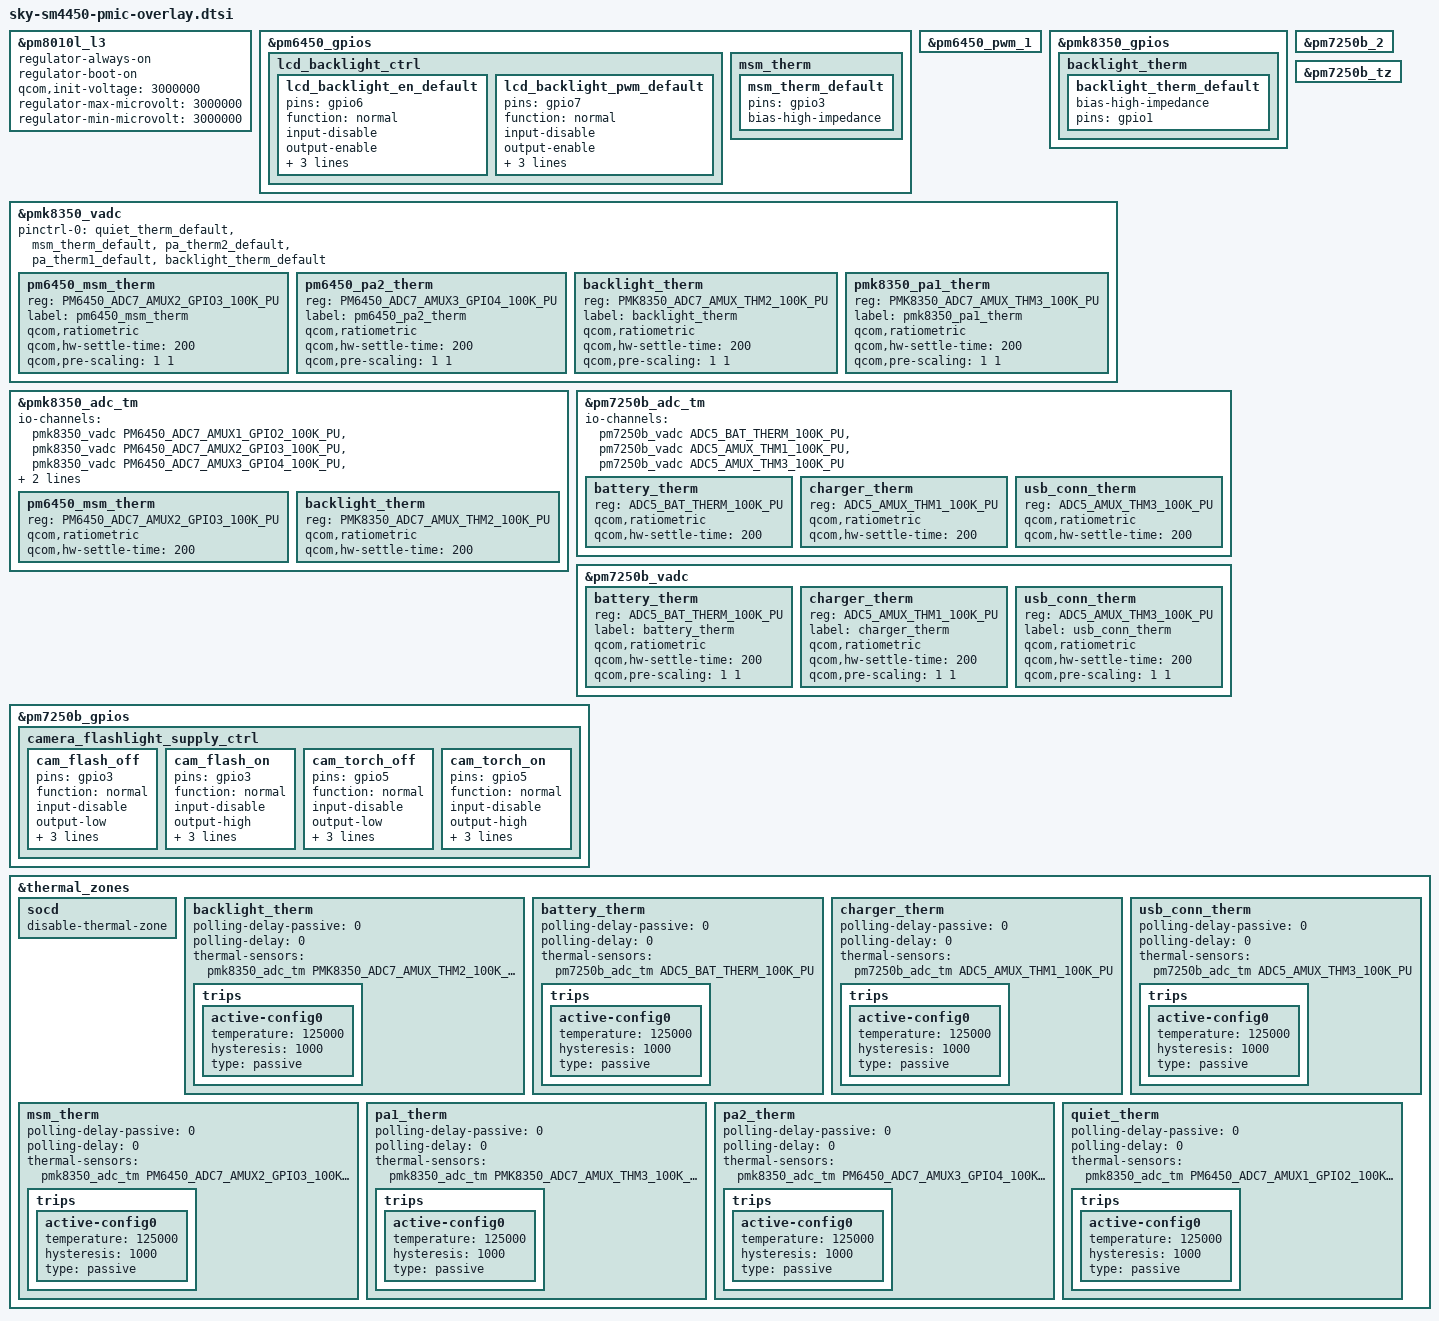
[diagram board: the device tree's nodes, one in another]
/*
 * Copyright (c) 2023 Atom-X-Devs.
 * Divyanshu-Modi <divyan.m05@gmail.com>
 *
 * Xiaomi SM4450 based SKY platform specific
 */

#include "ravelin-pmic-overlay.dtsi"
#include "ravelin-pm7250b.dtsi"

/*
 * PM8010 device specific diff for Xiaomi Sky platform
 */
&pm8010l_l3 {
	regulator-always-on;
	regulator-boot-on;
	qcom,init-voltage = <3000000>;
	regulator-max-microvolt = <3000000>;
	regulator-min-microvolt = <3000000>;
};

/*
 * PM6450 device specific diff for Xiaomi Sky platform
 */
&pm6450_gpios {
	/delete-node/ rear_cam_flash_therm;

	lcd_backlight_ctrl {
		lcd_backlight_en_default: lcd_backlight_en_default {
			pins = "gpio6";
			function = "normal";
			input-disable; /* No PULL */
			output-enable;
			bias-disable;
			power-source = <0>;
			drive-strength = <2>;
		};

		lcd_backlight_pwm_default: lcd_backlight_pwm_default {
			pins = "gpio7";
			function = "normal";
			input-disable; /* No PULL */
			output-enable;
			bias-disable;
			power-source = <1>;
			drive-strength = <2>;
		};
	};

	msm_therm {
		msm_therm_default: msm_therm_default {
			pins = "gpio3";
			bias-high-impedance;
		};
	};
};

&pm6450_pwm_1 {
	status = "ok";
};

/*
 * PMK8350 device specific diff for Xiaomi Sky platform
 */
&pmk8350_gpios {
	/delete-node/ wide_rfc_therm;

	backlight_therm {
		backlight_therm_default: backlight_therm_default {
			bias-high-impedance;
			pins = "gpio1";
		};
	};
};

&pmk8350_vadc {
	pinctrl-names = "default";
	pinctrl-0 = <&quiet_therm_default &msm_therm_default
			&pa_therm2_default &pa_therm1_default &backlight_therm_default>;

	/delete-node/ pmk8350_wide_rfc_therm;
	/delete-node/ pm6450_rear_cam_flash_therm;
	/delete-node/ pm6450_pa_therm2;
	/delete-node/ pmk8350_pa_therm1;

	pm6450_msm_therm {
		reg = <PM6450_ADC7_AMUX2_GPIO3_100K_PU>;
		label = "pm6450_msm_therm";
		qcom,ratiometric;
		qcom,hw-settle-time = <200>;
		qcom,pre-scaling = <1 1>;
	};

	pm6450_pa2_therm {
		reg = <PM6450_ADC7_AMUX3_GPIO4_100K_PU>;
		label = "pm6450_pa2_therm";
		qcom,ratiometric;
		qcom,hw-settle-time = <200>;
		qcom,pre-scaling = <1 1>;
	};

	backlight_therm {
		reg = <PMK8350_ADC7_AMUX_THM2_100K_PU>;
		label = "backlight_therm";
		qcom,ratiometric;
		qcom,hw-settle-time = <200>;
		qcom,pre-scaling = <1 1>;
	};

	pmk8350_pa1_therm {
		reg = <PMK8350_ADC7_AMUX_THM3_100K_PU>;
		label = "pmk8350_pa1_therm";
		qcom,ratiometric;
		qcom,hw-settle-time = <200>;
		qcom,pre-scaling = <1 1>;
	};
};

&pmk8350_adc_tm {
	/delete-node/ pmk8350_xo_therm;
	/delete-node/ pmk8350_wide_rfc_therm;
	/delete-node/ pm6450_rear_cam_flash_therm;

	io-channels = <&pmk8350_vadc PM6450_ADC7_AMUX1_GPIO2_100K_PU>,
			<&pmk8350_vadc PM6450_ADC7_AMUX2_GPIO3_100K_PU>,
			<&pmk8350_vadc PM6450_ADC7_AMUX3_GPIO4_100K_PU>,
			<&pmk8350_vadc PMK8350_ADC7_AMUX_THM2_100K_PU>,
			<&pmk8350_vadc PMK8350_ADC7_AMUX_THM3_100K_PU>;

	pm6450_msm_therm {
		reg = <PM6450_ADC7_AMUX2_GPIO3_100K_PU>;
		qcom,ratiometric;
		qcom,hw-settle-time = <200>;
	};

	backlight_therm {
		reg = <PMK8350_ADC7_AMUX_THM2_100K_PU>;
		qcom,ratiometric;
		qcom,hw-settle-time = <200>;
	};
};

/*
 * PMK7250B device specific diff for Xiaomi Sky platform
 */
&pm7250b_2 {
	/delete-node/ qcom,power-on@800;
};

&pm7250b_tz {
	/delete-property/ interrupts;
};

&pm7250b_adc_tm {
	/delete-node/ pm7250b_usb_conn_therm;
	/delete-node/ pm7250b_charger_skin_therm;

	io-channels = <&pm7250b_vadc ADC5_BAT_THERM_100K_PU>,
			<&pm7250b_vadc ADC5_AMUX_THM1_100K_PU>,
			<&pm7250b_vadc ADC5_AMUX_THM3_100K_PU>;

	battery_therm {
		reg = <ADC5_BAT_THERM_100K_PU>;
		qcom,ratiometric;
		qcom,hw-settle-time = <200>;
	};

	charger_therm {
		reg = <ADC5_AMUX_THM1_100K_PU>;
		qcom,ratiometric;
		qcom,hw-settle-time = <200>;
	};

	usb_conn_therm {
		reg = <ADC5_AMUX_THM3_100K_PU>;
		qcom,ratiometric;
		qcom,hw-settle-time = <200>;
	};
};

&pm7250b_vadc {
	/delete-node/ pm7250b_usb_conn_therm;
	/delete-node/ pm7250b_charger_skin_therm;

	battery_therm {
		reg = <ADC5_BAT_THERM_100K_PU>;
		label = "battery_therm";
		qcom,ratiometric;
		qcom,hw-settle-time = <200>;
		qcom,pre-scaling = <1 1>;
	};

	charger_therm {
		reg = <ADC5_AMUX_THM1_100K_PU>;
		label = "charger_therm";
		qcom,ratiometric;
		qcom,hw-settle-time = <200>;
		qcom,pre-scaling = <1 1>;
	};

	usb_conn_therm {
		reg = <ADC5_AMUX_THM3_100K_PU>;
		label = "usb_conn_therm";
		qcom,ratiometric;
		qcom,hw-settle-time = <200>;
		qcom,pre-scaling = <1 1>;
	};
};

&pm7250b_gpios {
	camera_flashlight_supply_ctrl {
		cam_flash_off: cam_flash_off {
			pins = "gpio3";
			function = "normal";
			input-disable; /* No PULL */
			output-low;
			bias-disable;
			power-source = <0>;
			drive-strength = <2>;
		};

		cam_flash_on: cam_flash_on {
			pins = "gpio3";
			function = "normal";
			input-disable; /* No PULL */
			output-high;
			bias-disable;
			power-source = <0>;
			drive-strength = <2>;
		};

		cam_torch_off: cam_torch_off {
			pins = "gpio5";
			function = "normal";
			input-disable; /* No PULL */
			output-low;
			bias-disable;
			power-source = <0>;
			drive-strength = <2>;
		};

		cam_torch_on: cam_torch_on {
			pins = "gpio5";
			function = "normal";
			input-disable; /* No PULL */
			output-high;
			bias-disable;
			power-source = <0>;
			drive-strength = <2>;
		};
	};
};

&thermal_zones {
	socd {
		disable-thermal-zone;
	};

	backlight_therm {
		polling-delay-passive = <0>;
		polling-delay = <0>;
		thermal-sensors = <&pmk8350_adc_tm PMK8350_ADC7_AMUX_THM2_100K_PU>;
		trips {
			active-config0 {
				temperature = <125000>;
				hysteresis = <1000>;
				type = "passive";
			};
		};
	};

	battery_therm {
		polling-delay-passive = <0>;
		polling-delay = <0>;
		thermal-sensors =  <&pm7250b_adc_tm ADC5_BAT_THERM_100K_PU>;
		trips {
			active-config0 {
				temperature = <125000>;
				hysteresis = <1000>;
				type = "passive";
			};
		};
	};

	charger_therm {
		polling-delay-passive = <0>;
		polling-delay = <0>;
		thermal-sensors =  <&pm7250b_adc_tm ADC5_AMUX_THM1_100K_PU>;
		trips {
			active-config0 {
				temperature = <125000>;
				hysteresis = <1000>;
				type = "passive";
			};
		};
	};

	msm_therm {
		polling-delay-passive = <0>;
		polling-delay = <0>;
		thermal-sensors = <&pmk8350_adc_tm PM6450_ADC7_AMUX2_GPIO3_100K_PU>;
		trips {
			active-config0 {
				temperature = <125000>;
				hysteresis = <1000>;
				type = "passive";
			};
		};
	};

	pa1_therm {
		polling-delay-passive = <0>;
		polling-delay = <0>;
		thermal-sensors = <&pmk8350_adc_tm PMK8350_ADC7_AMUX_THM3_100K_PU>;
		trips {
			active-config0 {
				temperature = <125000>;
				hysteresis = <1000>;
				type = "passive";
			};
		};
	};

	pa2_therm {
		polling-delay-passive = <0>;
		polling-delay = <0>;
		thermal-sensors = <&pmk8350_adc_tm PM6450_ADC7_AMUX3_GPIO4_100K_PU>;
		trips {
			active-config0 {
				temperature = <125000>;
				hysteresis = <1000>;
				type = "passive";
			};
		};
	};

	usb_conn_therm {
		polling-delay-passive = <0>;
		polling-delay = <0>;
		thermal-sensors =  <&pm7250b_adc_tm ADC5_AMUX_THM3_100K_PU>;
		trips {
			active-config0 {
				temperature = <125000>;
				hysteresis = <1000>;
				type = "passive";
			};
		};
	};

	quiet_therm {
		polling-delay-passive = <0>;
		polling-delay = <0>;
		thermal-sensors = <&pmk8350_adc_tm PM6450_ADC7_AMUX1_GPIO2_100K_PU>;
		trips {
			active-config0 {
				temperature = <125000>;
				hysteresis = <1000>;
				type = "passive";
			};
		};
	};
};
